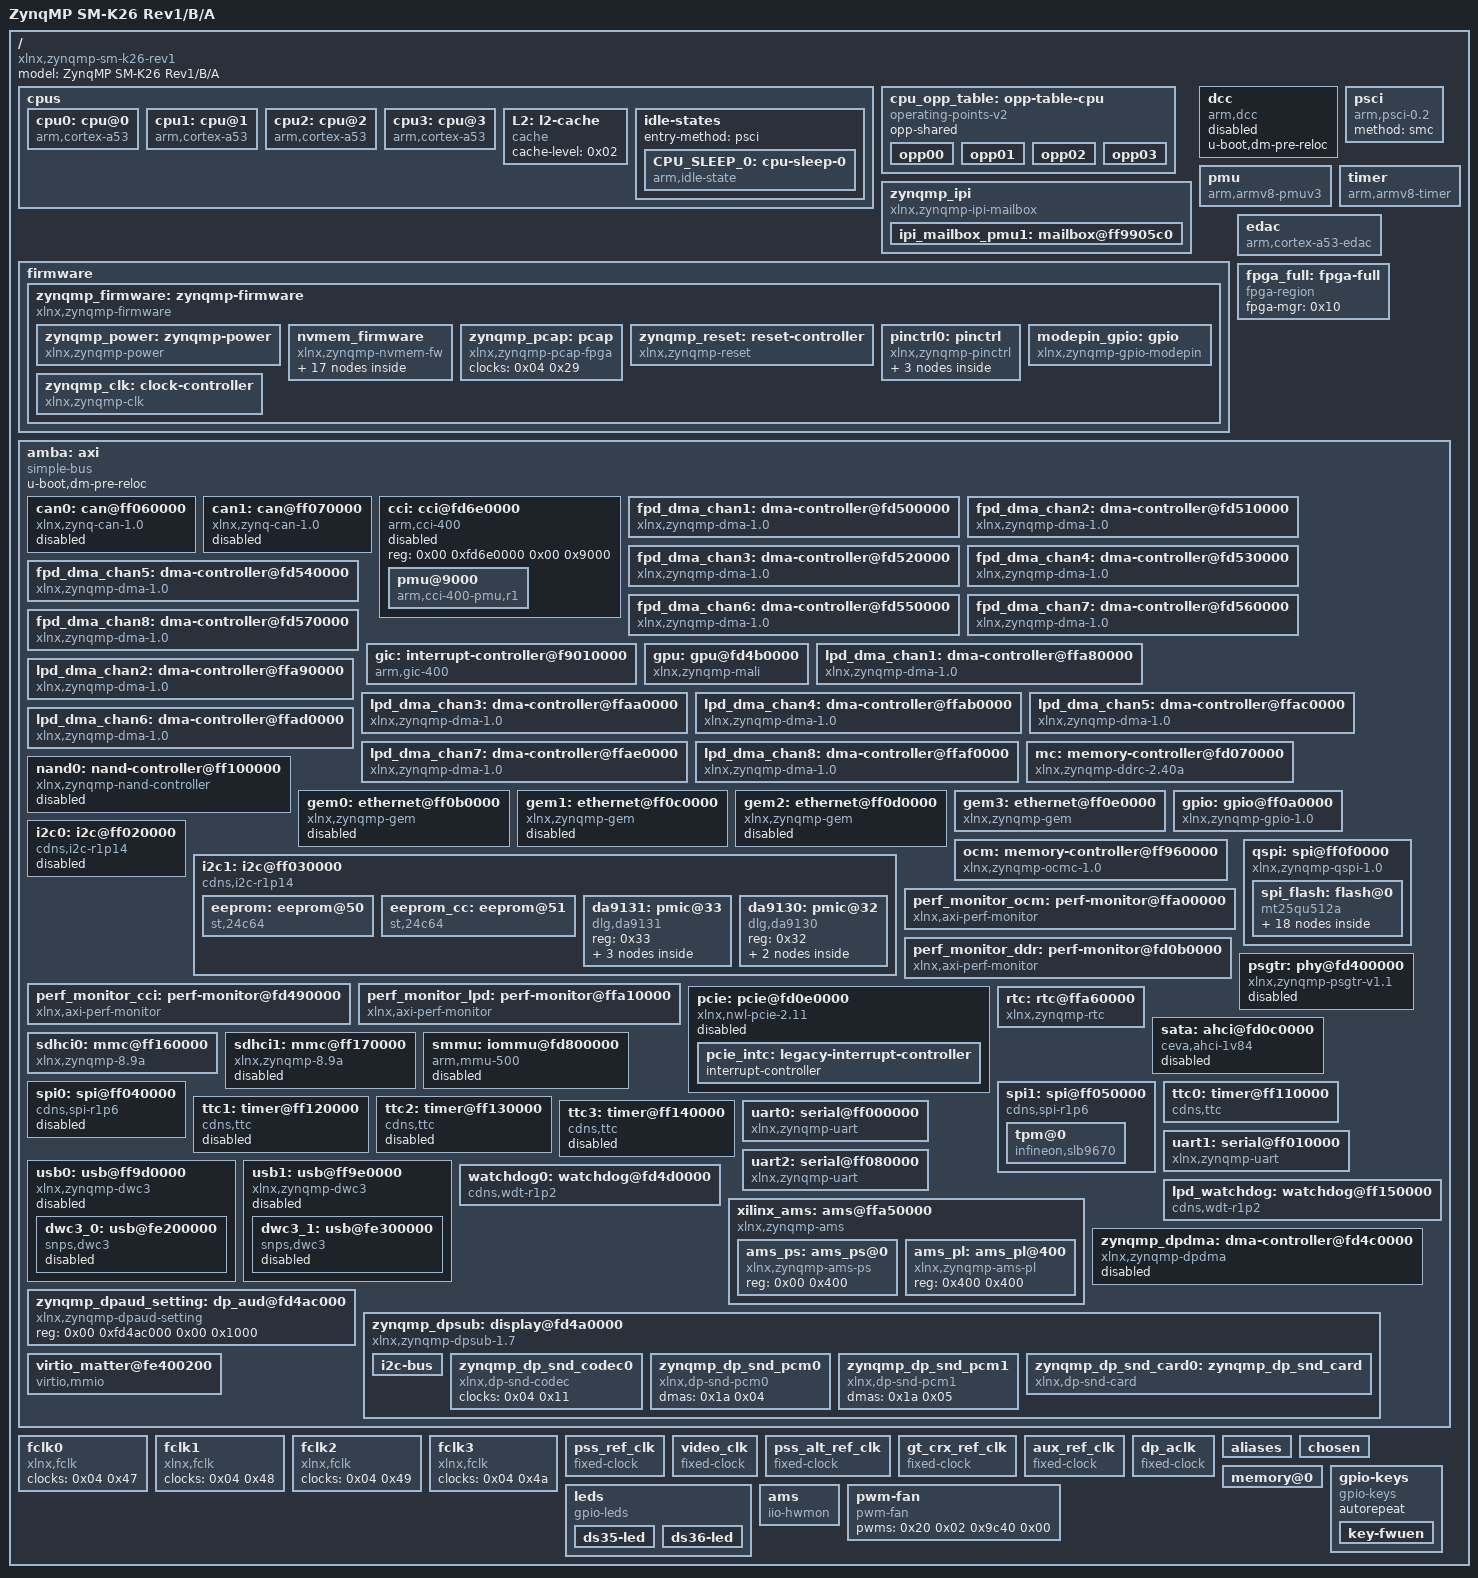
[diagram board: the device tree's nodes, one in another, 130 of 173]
/dts-v1/;

/ {
	compatible = "xlnx,zynqmp-sm-k26-rev1", "xlnx,zynqmp-sm-k26-revB", "xlnx,zynqmp-sm-k26-revA", "xlnx,zynqmp-sm-k26", "xlnx,zynqmp";
	#address-cells = <0x02>;
	#size-cells = <0x02>;
	model = "ZynqMP SM-K26 Rev1/B/A";

	cpus {
		#address-cells = <0x01>;
		#size-cells = <0x00>;

		cpu0: cpu@0 {
			compatible = "arm,cortex-a53";
			device_type = "cpu";
			enable-method = "psci";
			operating-points-v2 = <0x01>;
			reg = <0x00>;
			cpu-idle-states = <0x02>;
			next-level-cache = <0x03>;
			clocks = <0x04 0x0a>;
			phandle = <0x06>;
		};

		cpu1: cpu@1 {
			compatible = "arm,cortex-a53";
			device_type = "cpu";
			enable-method = "psci";
			reg = <0x01>;
			operating-points-v2 = <0x01>;
			cpu-idle-states = <0x02>;
			next-level-cache = <0x03>;
			phandle = <0x07>;
		};

		cpu2: cpu@2 {
			compatible = "arm,cortex-a53";
			device_type = "cpu";
			enable-method = "psci";
			reg = <0x02>;
			operating-points-v2 = <0x01>;
			cpu-idle-states = <0x02>;
			next-level-cache = <0x03>;
			phandle = <0x08>;
		};

		cpu3: cpu@3 {
			compatible = "arm,cortex-a53";
			device_type = "cpu";
			enable-method = "psci";
			reg = <0x03>;
			operating-points-v2 = <0x01>;
			cpu-idle-states = <0x02>;
			next-level-cache = <0x03>;
			phandle = <0x09>;
		};

		L2: l2-cache {
			compatible = "cache";
			cache-level = <0x02>;
			phandle = <0x03>;
		};

		idle-states {
			entry-method = "psci";

			CPU_SLEEP_0: cpu-sleep-0 {
				compatible = "arm,idle-state";
				arm,psci-suspend-param = <0x40000000>;
				local-timer-stop;
				entry-latency-us = <0x12c>;
				exit-latency-us = <0x258>;
				min-residency-us = <0x2710>;
				phandle = <0x02>;
			};
		};
	};

	cpu_opp_table: opp-table-cpu {
		compatible = "operating-points-v2";
		opp-shared;
		phandle = <0x01>;

		opp00 {
			opp-hz = <0x00 0x4f790d55>;
			opp-microvolt = <0xf4240>;
			clock-latency-ns = <0x7a120>;
		};

		opp01 {
			opp-hz = <0x00 0x27bc86aa>;
			opp-microvolt = <0xf4240>;
			clock-latency-ns = <0x7a120>;
		};

		opp02 {
			opp-hz = <0x00 0x1a7daf1c>;
			opp-microvolt = <0xf4240>;
			clock-latency-ns = <0x7a120>;
		};

		opp03 {
			opp-hz = <0x00 0x13de4355>;
			opp-microvolt = <0xf4240>;
			clock-latency-ns = <0x7a120>;
		};
	};

	zynqmp_ipi: zynqmp_ipi {
		u-boot,dm-pre-reloc;
		compatible = "xlnx,zynqmp-ipi-mailbox";
		interrupt-parent = <0x05>;
		interrupts = <0x00 0x23 0x04>;
		xlnx,ipi-id = <0x00>;
		#address-cells = <0x02>;
		#size-cells = <0x02>;
		ranges;
		phandle = <0x21>;

		ipi_mailbox_pmu1: mailbox@ff9905c0 {
			u-boot,dm-pre-reloc;
			reg = <0x00 0xff9905c0 0x00 0x20 0x00 0xff9905e0 0x00 0x20 0x00 0xff990e80 0x00 0x20 0x00 0xff990ea0 0x00 0x20>;
			reg-names = "local_request_region", "local_response_region", "remote_request_region", "remote_response_region";
			#mbox-cells = <0x01>;
			xlnx,ipi-id = <0x04>;
			phandle = <0x0a>;
		};
	};

	dcc: dcc {
		compatible = "arm,dcc";
		status = "disabled";
		u-boot,dm-pre-reloc;
		phandle = <0x22>;
	};

	pmu {
		compatible = "arm,armv8-pmuv3";
		interrupt-parent = <0x05>;
		interrupts = <0x00 0x8f 0x04 0x00 0x90 0x04 0x00 0x91 0x04 0x00 0x92 0x04>;
		interrupt-affinity = <0x06 0x07 0x08 0x09>;
	};

	psci {
		compatible = "arm,psci-0.2";
		method = "smc";
	};

	firmware {

		zynqmp_firmware: zynqmp-firmware {
			compatible = "xlnx,zynqmp-firmware";
			#power-domain-cells = <0x01>;
			method = "smc";
			u-boot,dm-pre-reloc;
			phandle = <0x11>;

			zynqmp_power: zynqmp-power {
				u-boot,dm-pre-reloc;
				compatible = "xlnx,zynqmp-power";
				interrupt-parent = <0x05>;
				interrupts = <0x00 0x23 0x04>;
				mboxes = <0x0a 0x00 0x0a 0x01>;
				mbox-names = "tx", "rx";
				phandle = <0x23>;
			};

			nvmem_firmware {
				compatible = "xlnx,zynqmp-nvmem-fw";
				#address-cells = <0x01>;
				#size-cells = <0x01>;

				soc_revision: soc_revision@0 {
					reg = <0x00 0x04>;
					phandle = <0x24>;
				};

				efuse_dna: efuse_dna@c {
					reg = <0x0c 0x0c>;
					phandle = <0x25>;
				};

				efuse_usr0: efuse_usr0@20 {
					reg = <0x20 0x04>;
					phandle = <0x26>;
				};

				efuse_usr1: efuse_usr1@24 {
					reg = <0x24 0x04>;
					phandle = <0x27>;
				};

				efuse_usr2: efuse_usr2@28 {
					reg = <0x28 0x04>;
					phandle = <0x28>;
				};

				efuse_usr3: efuse_usr3@2c {
					reg = <0x2c 0x04>;
					phandle = <0x29>;
				};

				efuse_usr4: efuse_usr4@30 {
					reg = <0x30 0x04>;
					phandle = <0x2a>;
				};

				efuse_usr5: efuse_usr5@34 {
					reg = <0x34 0x04>;
					phandle = <0x2b>;
				};

				efuse_usr6: efuse_usr6@38 {
					reg = <0x38 0x04>;
					phandle = <0x2c>;
				};

				efuse_usr7: efuse_usr7@3c {
					reg = <0x3c 0x04>;
					phandle = <0x2d>;
				};

				efuse_miscusr: efuse_miscusr@40 {
					reg = <0x40 0x04>;
					phandle = <0x2e>;
				};

				efuse_chash: efuse_chash@50 {
					reg = <0x50 0x04>;
					phandle = <0x2f>;
				};

				efuse_pufmisc: efuse_pufmisc@54 {
					reg = <0x54 0x04>;
					phandle = <0x30>;
				};

				efuse_sec: efuse_sec@58 {
					reg = <0x58 0x04>;
					phandle = <0x31>;
				};

				efuse_spkid: efuse_spkid@5c {
					reg = <0x5c 0x04>;
					phandle = <0x32>;
				};

				efuse_ppk0hash: efuse_ppk0hash@a0 {
					reg = <0xa0 0x30>;
					phandle = <0x33>;
				};

				efuse_ppk1hash: efuse_ppk1hash@d0 {
					reg = <0xd0 0x30>;
					phandle = <0x34>;
				};
			};

			zynqmp_pcap: pcap {
				compatible = "xlnx,zynqmp-pcap-fpga";
				clock-names = "ref_clk";
				clocks = <0x04 0x29>;
				phandle = <0x10>;
			};

			zynqmp_reset: reset-controller {
				compatible = "xlnx,zynqmp-reset";
				#reset-cells = <0x01>;
				phandle = <0x13>;
			};

			pinctrl0: pinctrl {
				compatible = "xlnx,zynqmp-pinctrl";
				status = "okay";
				phandle = <0x35>;

				pinctrl_sdhci0_default: sdhci0-default {
					phandle = <0x17>;

					conf {
						groups = "sdio0_0_grp";
						slew-rate = <0x01>;
						power-source = <0x01>;
						bias-disable;
					};

					mux {
						groups = "sdio0_0_grp";
						function = "sdio0";
					};
				};
			};

			modepin_gpio: gpio {
				compatible = "xlnx,zynqmp-gpio-modepin";
				gpio-controller;
				#gpio-cells = <0x02>;
				label = "modepin";
				phandle = <0x18>;
			};

			zynqmp_clk: clock-controller {
				u-boot,dm-pre-reloc;
				#clock-cells = <0x01>;
				compatible = "xlnx,zynqmp-clk";
				clocks = <0x0b 0x0c 0x0d 0x0e 0x0f>;
				clock-names = "pss_ref_clk", "video_clk", "pss_alt_ref_clk", "aux_ref_clk", "gt_crx_ref_clk";
				phandle = <0x04>;
			};
		};
	};

	timer {
		compatible = "arm,armv8-timer";
		interrupt-parent = <0x05>;
		interrupts = <0x01 0x0d 0xf08 0x01 0x0e 0xf08 0x01 0x0b 0xf08 0x01 0x0a 0xf08>;
	};

	edac {
		compatible = "arm,cortex-a53-edac";
	};

	fpga_full: fpga-full {
		compatible = "fpga-region";
		fpga-mgr = <0x10>;
		#address-cells = <0x02>;
		#size-cells = <0x02>;
		ranges;
		phandle = <0x36>;
	};

	amba: axi {
		compatible = "simple-bus";
		u-boot,dm-pre-reloc;
		#address-cells = <0x02>;
		#size-cells = <0x02>;
		ranges;
		phandle = <0x37>;

		can0: can@ff060000 {
			compatible = "xlnx,zynq-can-1.0";
			status = "disabled";
			clock-names = "can_clk", "pclk";
			reg = <0x00 0xff060000 0x00 0x1000>;
			interrupts = <0x00 0x17 0x04>;
			interrupt-parent = <0x05>;
			tx-fifo-depth = <0x40>;
			rx-fifo-depth = <0x40>;
			power-domains = <0x11 0x2f>;
			clocks = <0x04 0x3f 0x04 0x1f>;
			phandle = <0x38>;
		};

		can1: can@ff070000 {
			compatible = "xlnx,zynq-can-1.0";
			status = "disabled";
			clock-names = "can_clk", "pclk";
			reg = <0x00 0xff070000 0x00 0x1000>;
			interrupts = <0x00 0x18 0x04>;
			interrupt-parent = <0x05>;
			tx-fifo-depth = <0x40>;
			rx-fifo-depth = <0x40>;
			power-domains = <0x11 0x30>;
			clocks = <0x04 0x40 0x04 0x1f>;
			phandle = <0x39>;
		};

		cci: cci@fd6e0000 {
			compatible = "arm,cci-400";
			status = "disabled";
			reg = <0x00 0xfd6e0000 0x00 0x9000>;
			ranges = <0x00 0x00 0xfd6e0000 0x10000>;
			#address-cells = <0x01>;
			#size-cells = <0x01>;
			phandle = <0x3a>;

			pmu@9000 {
				compatible = "arm,cci-400-pmu,r1";
				reg = <0x9000 0x5000>;
				interrupt-parent = <0x05>;
				interrupts = <0x00 0x7b 0x04 0x00 0x7b 0x04 0x00 0x7b 0x04 0x00 0x7b 0x04 0x00 0x7b 0x04>;
			};
		};

		fpd_dma_chan1: dma-controller@fd500000 {
			status = "okay";
			compatible = "xlnx,zynqmp-dma-1.0";
			reg = <0x00 0xfd500000 0x00 0x1000>;
			interrupt-parent = <0x05>;
			interrupts = <0x00 0x7c 0x04>;
			clock-names = "clk_main", "clk_apb";
			#dma-cells = <0x01>;
			xlnx,bus-width = <0x80>;
			iommus = <0x12 0x14e8>;
			power-domains = <0x11 0x2a>;
			clocks = <0x04 0x13 0x04 0x1f>;
			phandle = <0x3b>;
		};

		fpd_dma_chan2: dma-controller@fd510000 {
			status = "okay";
			compatible = "xlnx,zynqmp-dma-1.0";
			reg = <0x00 0xfd510000 0x00 0x1000>;
			interrupt-parent = <0x05>;
			interrupts = <0x00 0x7d 0x04>;
			clock-names = "clk_main", "clk_apb";
			#dma-cells = <0x01>;
			xlnx,bus-width = <0x80>;
			iommus = <0x12 0x14e9>;
			power-domains = <0x11 0x2a>;
			clocks = <0x04 0x13 0x04 0x1f>;
			phandle = <0x3c>;
		};

		fpd_dma_chan3: dma-controller@fd520000 {
			status = "okay";
			compatible = "xlnx,zynqmp-dma-1.0";
			reg = <0x00 0xfd520000 0x00 0x1000>;
			interrupt-parent = <0x05>;
			interrupts = <0x00 0x7e 0x04>;
			clock-names = "clk_main", "clk_apb";
			#dma-cells = <0x01>;
			xlnx,bus-width = <0x80>;
			iommus = <0x12 0x14ea>;
			power-domains = <0x11 0x2a>;
			clocks = <0x04 0x13 0x04 0x1f>;
			phandle = <0x3d>;
		};

		fpd_dma_chan4: dma-controller@fd530000 {
			status = "okay";
			compatible = "xlnx,zynqmp-dma-1.0";
			reg = <0x00 0xfd530000 0x00 0x1000>;
			interrupt-parent = <0x05>;
			interrupts = <0x00 0x7f 0x04>;
			clock-names = "clk_main", "clk_apb";
			#dma-cells = <0x01>;
			xlnx,bus-width = <0x80>;
			iommus = <0x12 0x14eb>;
			power-domains = <0x11 0x2a>;
			clocks = <0x04 0x13 0x04 0x1f>;
			phandle = <0x3e>;
		};

		fpd_dma_chan5: dma-controller@fd540000 {
			status = "okay";
			compatible = "xlnx,zynqmp-dma-1.0";
			reg = <0x00 0xfd540000 0x00 0x1000>;
			interrupt-parent = <0x05>;
			interrupts = <0x00 0x80 0x04>;
			clock-names = "clk_main", "clk_apb";
			#dma-cells = <0x01>;
			xlnx,bus-width = <0x80>;
			iommus = <0x12 0x14ec>;
			power-domains = <0x11 0x2a>;
			clocks = <0x04 0x13 0x04 0x1f>;
			phandle = <0x3f>;
		};

		fpd_dma_chan6: dma-controller@fd550000 {
			status = "okay";
			compatible = "xlnx,zynqmp-dma-1.0";
			reg = <0x00 0xfd550000 0x00 0x1000>;
			interrupt-parent = <0x05>;
			interrupts = <0x00 0x81 0x04>;
			clock-names = "clk_main", "clk_apb";
			#dma-cells = <0x01>;
			xlnx,bus-width = <0x80>;
			iommus = <0x12 0x14ed>;
			power-domains = <0x11 0x2a>;
			clocks = <0x04 0x13 0x04 0x1f>;
			phandle = <0x40>;
		};

		fpd_dma_chan7: dma-controller@fd560000 {
			status = "okay";
			compatible = "xlnx,zynqmp-dma-1.0";
			reg = <0x00 0xfd560000 0x00 0x1000>;
			interrupt-parent = <0x05>;
			interrupts = <0x00 0x82 0x04>;
			clock-names = "clk_main", "clk_apb";
			#dma-cells = <0x01>;
			xlnx,bus-width = <0x80>;
			iommus = <0x12 0x14ee>;
			power-domains = <0x11 0x2a>;
			clocks = <0x04 0x13 0x04 0x1f>;
			phandle = <0x41>;
		};

		fpd_dma_chan8: dma-controller@fd570000 {
			status = "okay";
			compatible = "xlnx,zynqmp-dma-1.0";
			reg = <0x00 0xfd570000 0x00 0x1000>;
			interrupt-parent = <0x05>;
			interrupts = <0x00 0x83 0x04>;
			clock-names = "clk_main", "clk_apb";
			#dma-cells = <0x01>;
			xlnx,bus-width = <0x80>;
			iommus = <0x12 0x14ef>;
			power-domains = <0x11 0x2a>;
			clocks = <0x04 0x13 0x04 0x1f>;
			phandle = <0x42>;
		};

		gic: interrupt-controller@f9010000 {
			compatible = "arm,gic-400";
			#interrupt-cells = <0x03>;
			reg = <0x00 0xf9010000 0x00 0x10000 0x00 0xf9020000 0x00 0x20000 0x00 0xf9040000 0x00 0x20000 0x00 0xf9060000 0x00 0x20000>;
			interrupt-controller;
			interrupt-parent = <0x05>;
			interrupts = <0x01 0x09 0xf04>;
			phandle = <0x05>;
		};

		gpu: gpu@fd4b0000 {
			status = "okay";
			compatible = "xlnx,zynqmp-mali", "arm,mali-400";
			reg = <0x00 0xfd4b0000 0x00 0x10000>;
			interrupt-parent = <0x05>;
			interrupts = <0x00 0x84 0x04 0x00 0x84 0x04 0x00 0x84 0x04 0x00 0x84 0x04 0x00 0x84 0x04 0x00 0x84 0x04>;
			interrupt-names = "gp", "gpmmu", "pp0", "ppmmu0", "pp1", "ppmmu1";
			clock-names = "bus", "core";
			power-domains = <0x11 0x3a>;
			clocks = <0x04 0x18 0x04 0x19>;
			phandle = <0x43>;
		};

		lpd_dma_chan1: dma-controller@ffa80000 {
			status = "okay";
			compatible = "xlnx,zynqmp-dma-1.0";
			reg = <0x00 0xffa80000 0x00 0x1000>;
			interrupt-parent = <0x05>;
			interrupts = <0x00 0x4d 0x04>;
			clock-names = "clk_main", "clk_apb";
			#dma-cells = <0x01>;
			xlnx,bus-width = <0x40>;
			power-domains = <0x11 0x2b>;
			clocks = <0x04 0x44 0x04 0x1f>;
			phandle = <0x44>;
		};

		lpd_dma_chan2: dma-controller@ffa90000 {
			status = "okay";
			compatible = "xlnx,zynqmp-dma-1.0";
			reg = <0x00 0xffa90000 0x00 0x1000>;
			interrupt-parent = <0x05>;
			interrupts = <0x00 0x4e 0x04>;
			clock-names = "clk_main", "clk_apb";
			#dma-cells = <0x01>;
			xlnx,bus-width = <0x40>;
			power-domains = <0x11 0x2b>;
			clocks = <0x04 0x44 0x04 0x1f>;
			phandle = <0x45>;
		};

		lpd_dma_chan3: dma-controller@ffaa0000 {
			status = "okay";
			compatible = "xlnx,zynqmp-dma-1.0";
			reg = <0x00 0xffaa0000 0x00 0x1000>;
			interrupt-parent = <0x05>;
			interrupts = <0x00 0x4f 0x04>;
			clock-names = "clk_main", "clk_apb";
			#dma-cells = <0x01>;
			xlnx,bus-width = <0x40>;
			power-domains = <0x11 0x2b>;
			clocks = <0x04 0x44 0x04 0x1f>;
			phandle = <0x46>;
		};

		lpd_dma_chan4: dma-controller@ffab0000 {
			status = "okay";
			compatible = "xlnx,zynqmp-dma-1.0";
			reg = <0x00 0xffab0000 0x00 0x1000>;
			interrupt-parent = <0x05>;
			interrupts = <0x00 0x50 0x04>;
			clock-names = "clk_main", "clk_apb";
			#dma-cells = <0x01>;
			xlnx,bus-width = <0x40>;
			power-domains = <0x11 0x2b>;
			clocks = <0x04 0x44 0x04 0x1f>;
			phandle = <0x47>;
		};

		lpd_dma_chan5: dma-controller@ffac0000 {
			status = "okay";
			compatible = "xlnx,zynqmp-dma-1.0";
			reg = <0x00 0xffac0000 0x00 0x1000>;
			interrupt-parent = <0x05>;
			interrupts = <0x00 0x51 0x04>;
			clock-names = "clk_main", "clk_apb";
			#dma-cells = <0x01>;
			xlnx,bus-width = <0x40>;
			power-domains = <0x11 0x2b>;
			clocks = <0x04 0x44 0x04 0x1f>;
			phandle = <0x48>;
		};

		lpd_dma_chan6: dma-controller@ffad0000 {
			status = "okay";
			compatible = "xlnx,zynqmp-dma-1.0";
			reg = <0x00 0xffad0000 0x00 0x1000>;
			interrupt-parent = <0x05>;
			interrupts = <0x00 0x52 0x04>;
			clock-names = "clk_main", "clk_apb";
			#dma-cells = <0x01>;
			xlnx,bus-width = <0x40>;
			power-domains = <0x11 0x2b>;
			clocks = <0x04 0x44 0x04 0x1f>;
			phandle = <0x49>;
		};

		lpd_dma_chan7: dma-controller@ffae0000 {
			status = "okay";
			compatible = "xlnx,zynqmp-dma-1.0";
			reg = <0x00 0xffae0000 0x00 0x1000>;
			interrupt-parent = <0x05>;
			interrupts = <0x00 0x53 0x04>;
			clock-names = "clk_main", "clk_apb";
			#dma-cells = <0x01>;
			xlnx,bus-width = <0x40>;
			power-domains = <0x11 0x2b>;
			clocks = <0x04 0x44 0x04 0x1f>;
			phandle = <0x4a>;
		};

		lpd_dma_chan8: dma-controller@ffaf0000 {
			status = "okay";
			compatible = "xlnx,zynqmp-dma-1.0";
			reg = <0x00 0xffaf0000 0x00 0x1000>;
			interrupt-parent = <0x05>;
			interrupts = <0x00 0x54 0x04>;
			clock-names = "clk_main", "clk_apb";
			#dma-cells = <0x01>;
			xlnx,bus-width = <0x40>;
			power-domains = <0x11 0x2b>;
			clocks = <0x04 0x44 0x04 0x1f>;
			phandle = <0x4b>;
		};

		mc: memory-controller@fd070000 {
			compatible = "xlnx,zynqmp-ddrc-2.40a";
			reg = <0x00 0xfd070000 0x00 0x30000>;
			interrupt-parent = <0x05>;
			interrupts = <0x00 0x70 0x04>;
			phandle = <0x4c>;
		};

		nand0: nand-controller@ff100000 {
			compatible = "xlnx,zynqmp-nand-controller", "arasan,nfc-v3p10";
			status = "disabled";
			reg = <0x00 0xff100000 0x00 0x1000>;
			clock-names = "controller", "bus";
			interrupt-parent = <0x05>;
			interrupts = <0x00 0x0e 0x04>;
			#address-cells = <0x01>;
			#size-cells = <0x00>;
			iommus = <0x12 0x872>;
			power-domains = <0x11 0x2c>;
			clocks = <0x04 0x3c 0x04 0x1f>;
			phandle = <0x4d>;
		};

		gem0: ethernet@ff0b0000 {
			compatible = "xlnx,zynqmp-gem", "cdns,gem";
			status = "disabled";
			interrupt-parent = <0x05>;
			interrupts = <0x00 0x39 0x04 0x00 0x39 0x04>;
			reg = <0x00 0xff0b0000 0x00 0x1000>;
			clock-names = "pclk", "hclk", "tx_clk", "rx_clk", "tsu_clk";
			#address-cells = <0x01>;
			#size-cells = <0x00>;
			iommus = <0x12 0x874>;
			power-domains = <0x11 0x1d>;
			resets = <0x13 0x1d>;
			reset-names = "gem0_rst";
			clocks = <0x04 0x1f 0x04 0x68 0x04 0x2d 0x04 0x31 0x04 0x2c>;
			phandle = <0x4e>;
		};

		gem1: ethernet@ff0c0000 {
			compatible = "xlnx,zynqmp-gem", "cdns,gem";
			status = "disabled";
			interrupt-parent = <0x05>;
			interrupts = <0x00 0x3b 0x04 0x00 0x3b 0x04>;
			reg = <0x00 0xff0c0000 0x00 0x1000>;
			clock-names = "pclk", "hclk", "tx_clk", "rx_clk", "tsu_clk";
			#address-cells = <0x01>;
			#size-cells = <0x00>;
			iommus = <0x12 0x875>;
			power-domains = <0x11 0x1e>;
			resets = <0x13 0x1e>;
			reset-names = "gem1_rst";
			clocks = <0x04 0x1f 0x04 0x69 0x04 0x2e 0x04 0x32 0x04 0x2c>;
			phandle = <0x4f>;
		};

		gem2: ethernet@ff0d0000 {
			compatible = "xlnx,zynqmp-gem", "cdns,gem";
			status = "disabled";
			interrupt-parent = <0x05>;
			interrupts = <0x00 0x3d 0x04 0x00 0x3d 0x04>;
			reg = <0x00 0xff0d0000 0x00 0x1000>;
			clock-names = "pclk", "hclk", "tx_clk", "rx_clk", "tsu_clk";
			#address-cells = <0x01>;
			#size-cells = <0x00>;
			iommus = <0x12 0x876>;
			power-domains = <0x11 0x1f>;
			resets = <0x13 0x1f>;
			reset-names = "gem2_rst";
			clocks = <0x04 0x1f 0x04 0x6a 0x04 0x2f 0x04 0x33 0x04 0x2c>;
			phandle = <0x50>;
		};

		gem3: ethernet@ff0e0000 {
			compatible = "xlnx,zynqmp-gem", "cdns,gem";
			status = "okay";
			interrupt-parent = <0x05>;
			interrupts = <0x00 0x3f 0x04 0x00 0x3f 0x04>;
			reg = <0x00 0xff0e0000 0x00 0x1000>;
			clock-names = "pclk", "hclk", "tx_clk", "rx_clk", "tsu_clk";
			#address-cells = <0x01>;
			#size-cells = <0x00>;
			iommus = <0x12 0x877>;
			power-domains = <0x11 0x20>;
			resets = <0x13 0x20>;
			reset-names = "gem3_rst";
			clocks = <0x04 0x1f 0x04 0x6b 0x04 0x30 0x04 0x34 0x04 0x2c>;
			phandle = <0x51>;
		};

		gpio: gpio@ff0a0000 {
			compatible = "xlnx,zynqmp-gpio-1.0";
			status = "okay";
			#gpio-cells = <0x02>;
			gpio-controller;
			interrupt-parent = <0x05>;
			interrupts = <0x00 0x10 0x04>;
			interrupt-controller;
			#interrupt-cells = <0x02>;
			reg = <0x00 0xff0a0000 0x00 0x1000>;
			power-domains = <0x11 0x2e>;
			clocks = <0x04 0x1f>;
			gpio-line-names = "QSPI_CLK", "QSPI_DQ1", "QSPI_DQ2", "QSPI_DQ3", "QSPI_DQ0", "QSPI_CS_B", "SPI_CLK", "LED1", "LED2", "SPI_CS_B", "SPI_MISO", "SPI_MOSI", "FWUEN", "EMMC_DAT0", "EMMC_DAT1", "EMMC_DAT2", "EMMC_DAT3", "EMMC_DAT4", "EMMC_DAT5", "EMMC_DAT6", "EMMC_DAT7", "EMMC_CMD", "EMMC_CLK", "EMMC_RST", "I2C1_SCL", "I2C1_SDA", "", "", "", "", "", "", "", "", "", "", "", "", "", "", "", "", "", "", "", "", "", "", "", "", "", "", "", "", "", "", "", "", "", "", "", "", "", "", "", "", "", "", "", "", "", "", "", "", "", "", "", "", "", "", "", "", "", "", "", "", "", "", "", "", "", "", "", "", "", "", "", "", "", "", "", "", "", "", "", "", "", "", "", "", "", "", "", "", "", "", "", "", "", "", "", "", "", "", "", "", "", "", "", "", "", "", "", "", "", "", "", "", "", "", "", "", "", "", "", "", "", "", "", "", "", "", "", "", "", "", "", "", "", "", "", "", "", "", "", "", "", "", "", "", "", "", "", "";
			phandle = <0x14>;
		};

		i2c0: i2c@ff020000 {
			compatible = "cdns,i2c-r1p14";
			status = "disabled";
			interrupt-parent = <0x05>;
			interrupts = <0x00 0x11 0x04>;
			reg = <0x00 0xff020000 0x00 0x1000>;
			#address-cells = <0x01>;
			#size-cells = <0x00>;
			power-domains = <0x11 0x25>;
			clocks = <0x04 0x3d>;
			phandle = <0x52>;
		};

		i2c1: i2c@ff030000 {
			compatible = "cdns,i2c-r1p14";
			status = "okay";
			interrupt-parent = <0x05>;
			interrupts = <0x00 0x12 0x04>;
			reg = <0x00 0xff030000 0x00 0x1000>;
			#address-cells = <0x01>;
			#size-cells = <0x00>;
			power-domains = <0x11 0x26>;
			clocks = <0x04 0x3e>;
			u-boot,dm-pre-reloc;
			clock-frequency = <0x61a80>;
			scl-gpios = <0x14 0x18 0x00>;
			sda-gpios = <0x14 0x19 0x00>;
			phandle = <0x53>;

			eeprom: eeprom@50 {
				u-boot,dm-pre-reloc;
				compatible = "st,24c64", "atmel,24c64";
				reg = <0x50>;
				phandle = <0x54>;
			};

			eeprom_cc: eeprom@51 {
				u-boot,dm-pre-reloc;
				compatible = "st,24c64", "atmel,24c64";
				reg = <0x51>;
				phandle = <0x55>;
			};

			da9131: pmic@33 {
				compatible = "dlg,da9131";
				reg = <0x33>;
				phandle = <0x56>;

				regulators {

					da9131_buck1: buck1 {
						regulator-name = "da9131_buck1";
						regulator-boot-on;
						regulator-always-on;
						phandle = <0x57>;
					};

					da9131_buck2: buck2 {
						regulator-name = "da9131_buck2";
						regulator-boot-on;
						regulator-always-on;
						phandle = <0x58>;
					};
				};
			};

			da9130: pmic@32 {
				compatible = "dlg,da9130";
				reg = <0x32>;
				phandle = <0x59>;

				regulators {

					da9130_buck1: buck1 {
						regulator-name = "da9130_buck1";
						regulator-boot-on;
						regulator-always-on;
						phandle = <0x5a>;
					};
				};
			};
		};

		ocm: memory-controller@ff960000 {
			compatible = "xlnx,zynqmp-ocmc-1.0";
			reg = <0x00 0xff960000 0x00 0x1000>;
			interrupt-parent = <0x05>;
			interrupts = <0x00 0x0a 0x04>;
			phandle = <0x5b>;
		};

		perf_monitor_ocm: perf-monitor@ffa00000 {
			compatible = "xlnx,axi-perf-monitor";
			reg = <0x00 0xffa00000 0x00 0x10000>;
			interrupts = <0x00 0x19 0x04>;
			interrupt-parent = <0x05>;
			xlnx,enable-profile = <0x00>;
			xlnx,enable-trace = <0x00>;
			xlnx,num-monitor-slots = <0x01>;
			xlnx,enable-event-count = <0x01>;
			xlnx,enable-event-log = <0x01>;
			xlnx,have-sampled-metric-cnt = <0x01>;
			xlnx,num-of-counters = <0x08>;
			xlnx,metric-count-width = <0x20>;
			xlnx,metrics-sample-count-width = <0x20>;
			xlnx,global-count-width = <0x20>;
			xlnx,metric-count-scale = <0x01>;
			clocks = <0x04 0x1f>;
			phandle = <0x5c>;
		};

		perf_monitor_ddr: perf-monitor@fd0b0000 {
			compatible = "xlnx,axi-perf-monitor";
			reg = <0x00 0xfd0b0000 0x00 0x10000>;
			interrupts = <0x00 0x7b 0x04>;
			interrupt-parent = <0x05>;
			xlnx,enable-profile = <0x00>;
			xlnx,enable-trace = <0x00>;
			xlnx,num-monitor-slots = <0x06>;
			xlnx,enable-event-count = <0x01>;
			xlnx,enable-event-log = <0x00>;
			xlnx,have-sampled-metric-cnt = <0x01>;
			xlnx,num-of-counters = <0x0a>;
			xlnx,metric-count-width = <0x20>;
			xlnx,metrics-sample-count-width = <0x20>;
			xlnx,global-count-width = <0x20>;
			xlnx,metric-count-scale = <0x01>;
			clocks = <0x04 0x1c>;
			phandle = <0x5d>;
		};

		perf_monitor_cci: perf-monitor@fd490000 {
			compatible = "xlnx,axi-perf-monitor";
			reg = <0x00 0xfd490000 0x00 0x10000>;
			interrupts = <0x00 0x7b 0x04>;
			interrupt-parent = <0x05>;
			xlnx,enable-profile = <0x00>;
			xlnx,enable-trace = <0x00>;
			xlnx,num-monitor-slots = <0x01>;
			xlnx,enable-event-count = <0x01>;
			xlnx,enable-event-log = <0x00>;
			xlnx,have-sampled-metric-cnt = <0x01>;
			xlnx,num-of-counters = <0x08>;
			xlnx,metric-count-width = <0x20>;
			xlnx,metrics-sample-count-width = <0x20>;
			xlnx,global-count-width = <0x20>;
			xlnx,metric-count-scale = <0x01>;
			clocks = <0x04 0x1c>;
			phandle = <0x5e>;
		};

		perf_monitor_lpd: perf-monitor@ffa10000 {
			compatible = "xlnx,axi-perf-monitor";
			reg = <0x00 0xffa10000 0x00 0x10000>;
			interrupts = <0x00 0x19 0x04>;
			interrupt-parent = <0x05>;
			xlnx,enable-profile = <0x00>;
			xlnx,enable-trace = <0x00>;
			xlnx,num-monitor-slots = <0x01>;
			xlnx,enable-event-count = <0x01>;
			xlnx,enable-event-log = <0x01>;
			xlnx,have-sampled-metric-cnt = <0x01>;
			xlnx,num-of-counters = <0x08>;
			xlnx,metric-count-width = <0x20>;
			xlnx,metrics-sample-count-width = <0x20>;
			xlnx,global-count-width = <0x20>;
			xlnx,metric-count-scale = <0x01>;
			clocks = <0x04 0x1f>;
			phandle = <0x5f>;
		};

		pcie: pcie@fd0e0000 {
			compatible = "xlnx,nwl-pcie-2.11";
			status = "disabled";
			#address-cells = <0x03>;
			#size-cells = <0x02>;
			#interrupt-cells = <0x01>;
			msi-controller;
			device_type = "pci";
			interrupt-parent = <0x05>;
			interrupts = <0x00 0x76 0x04 0x00 0x75 0x04 0x00 0x74 0x04 0x00 0x73 0x04 0x00 0x72 0x04>;
			interrupt-names = "misc", "dummy", "intx", "msi1", "msi0";
			msi-parent = <0x15>;
			reg = <0x00 0xfd0e0000 0x00 0x1000 0x00 0xfd480000 0x00 0x1000 0x80 0x00 0x00 0x1000000>;
			reg-names = "breg", "pcireg", "cfg";
			ranges = <0x2000000 0x00 0xe0000000 0x00 0xe0000000 0x00 0x10000000 0x43000000 0x06 0x00 0x06 0x00 0x02 0x00>;
			bus-range = <0x00 0xff>;
			interrupt-map-mask = <0x00 0x00 0x00 0x07>;
			interrupt-map = <0x00 0x00 0x00 0x01 0x16 0x01 0x00 0x00 0x00 0x02 0x16 0x02 0x00 0x00 0x00 0x03 0x16 0x03 0x00 0x00 0x00 0x04 0x16 0x04>;
			iommus = <0x12 0x4d0>;
			power-domains = <0x11 0x3b>;
			clocks = <0x04 0x17>;
			phandle = <0x15>;

			pcie_intc: legacy-interrupt-controller {
				interrupt-controller;
				#address-cells = <0x00>;
				#interrupt-cells = <0x01>;
				phandle = <0x16>;
			};
		};

		qspi: spi@ff0f0000 {
			u-boot,dm-pre-reloc;
			compatible = "xlnx,zynqmp-qspi-1.0";
			status = "okay";
			clock-names = "ref_clk", "pclk";
			interrupts = <0x00 0x0f 0x04>;
			interrupt-parent = <0x05>;
			num-cs = <0x01>;
			reg = <0x00 0xff0f0000 0x00 0x1000 0x00 0xc0000000 0x00 0x8000000>;
			#address-cells = <0x01>;
			#size-cells = <0x00>;
			iommus = <0x12 0x873>;
			power-domains = <0x11 0x2d>;
			clocks = <0x04 0x35 0x04 0x1f>;
			phandle = <0x60>;

			spi_flash: flash@0 {
				compatible = "mt25qu512a", "jedec,spi-nor";
				#address-cells = <0x01>;
				#size-cells = <0x01>;
				reg = <0x00>;
				spi-tx-bus-width = <0x04>;
				spi-rx-bus-width = <0x04>;
				spi-max-frequency = <0x2625a00>;
				phandle = <0x61>;

				partitions {
					compatible = "fixed-partitions";
					#address-cells = <0x01>;
					#size-cells = <0x01>;

					partition@0 {
						label = "Image Selector";
						reg = <0x00 0x80000>;
						read-only;
						lock;
					};

					partition@80000 {
						label = "Image Selector Golden";
						reg = <0x80000 0x80000>;
						read-only;
						lock;
					};

					partition@100000 {
						label = "Persistent Register";
						reg = <0x100000 0x20000>;
					};

					partition@120000 {
						label = "Persistent Register Backup";
						reg = <0x120000 0x20000>;
					};

					partition@140000 {
						label = "Open_1";
						reg = <0x140000 0xc0000>;
					};

					partition@200000 {
						label = "Image A (FSBL, PMU, ATF, U-Boot)";
						reg = <0x200000 0xd00000>;
					};

					partition@f00000 {
						label = "ImgSel Image A Catch";
						reg = <0xf00000 0x80000>;
						read-only;
						lock;
					};

					partition@f80000 {
						label = "Image B (FSBL, PMU, ATF, U-Boot)";
						reg = <0xf80000 0xd00000>;
					};

					partition@1c80000 {
						label = "ImgSel Image B Catch";
						reg = <0x1c80000 0x80000>;
						read-only;
						lock;
					};

					partition@1d00000 {
						label = "Open_2";
						reg = <0x1d00000 0x100000>;
					};

					partition@1e00000 {
						label = "Recovery Image";
						reg = <0x1e00000 0x200000>;
						read-only;
						lock;
					};

					partition@2000000 {
						label = "Recovery Image Backup";
						reg = <0x2000000 0x200000>;
						read-only;
						lock;
					};

					partition@2200000 {
						label = "U-Boot storage variables";
						reg = <0x2200000 0x20000>;
					};

					partition@2220000 {
						label = "U-Boot storage variables backup";
						reg = <0x2220000 0x20000>;
					};

					partition@2240000 {
						label = "SHA256";
						reg = <0x2240000 0x40000>;
						read-only;
						lock;
					};

					partition@2280000 {
						label = "Secure OS Storage";
						reg = <0x2280000 0x20000>;
					};

					partition@22A0000 {
						label = "User";
						reg = <0x22a0000 0x1db0000>;
					};
				};
			};
		};

		psgtr: phy@fd400000 {
			compatible = "xlnx,zynqmp-psgtr-v1.1";
			status = "disabled";
			reg = <0x00 0xfd400000 0x00 0x40000 0x00 0xfd3d0000 0x00 0x1000>;
			reg-names = "serdes", "siou";
			#phy-cells = <0x04>;
			phandle = <0x62>;
		};

		rtc: rtc@ffa60000 {
			compatible = "xlnx,zynqmp-rtc";
			status = "okay";
			reg = <0x00 0xffa60000 0x00 0x100>;
			interrupt-parent = <0x05>;
			interrupts = <0x00 0x1a 0x04 0x00 0x1b 0x04>;
			interrupt-names = "alarm", "sec";
			calibration = <0x7fff>;
			phandle = <0x63>;
		};

		sata: ahci@fd0c0000 {
			compatible = "ceva,ahci-1v84";
			status = "disabled";
			reg = <0x00 0xfd0c0000 0x00 0x2000>;
			interrupt-parent = <0x05>;
			interrupts = <0x00 0x85 0x04>;
			power-domains = <0x11 0x1c>;
			resets = <0x13 0x10>;
			clocks = <0x04 0x16>;
			phandle = <0x64>;
		};

		sdhci0: mmc@ff160000 {
			u-boot,dm-pre-reloc;
			compatible = "xlnx,zynqmp-8.9a", "arasan,sdhci-8.9a";
			status = "okay";
			interrupt-parent = <0x05>;
			interrupts = <0x00 0x30 0x04>;
			reg = <0x00 0xff160000 0x00 0x1000>;
			clock-names = "clk_xin", "clk_ahb";
			iommus = <0x12 0x870>;
			#clock-cells = <0x01>;
			clock-output-names = "clk_out_sd0", "clk_in_sd0";
			power-domains = <0x11 0x27>;
			resets = <0x13 0x26>;
			clocks = <0x04 0x36 0x04 0x1f>;
			assigned-clocks = <0x04 0x36>;
			pinctrl-names = "default";
			pinctrl-0 = <0x17>;
			non-removable;
			disable-wp;
			bus-width = <0x08>;
			xlnx,mio-bank = <0x00>;
			assigned-clock-rates = <0xb2cfe8b>;
			phandle = <0x65>;
		};

		sdhci1: mmc@ff170000 {
			u-boot,dm-pre-reloc;
			compatible = "xlnx,zynqmp-8.9a", "arasan,sdhci-8.9a";
			status = "disabled";
			interrupt-parent = <0x05>;
			interrupts = <0x00 0x31 0x04>;
			reg = <0x00 0xff170000 0x00 0x1000>;
			clock-names = "clk_xin", "clk_ahb";
			iommus = <0x12 0x871>;
			#clock-cells = <0x01>;
			clock-output-names = "clk_out_sd1", "clk_in_sd1";
			power-domains = <0x11 0x28>;
			resets = <0x13 0x27>;
			clocks = <0x04 0x37 0x04 0x1f>;
			assigned-clocks = <0x04 0x37>;
			phandle = <0x66>;
		};

		smmu: iommu@fd800000 {
			compatible = "arm,mmu-500";
			reg = <0x00 0xfd800000 0x00 0x20000>;
			#iommu-cells = <0x01>;
			status = "disabled";
			#global-interrupts = <0x01>;
			interrupt-parent = <0x05>;
			interrupts = <0x00 0x9b 0x04 0x00 0x9b 0x04 0x00 0x9b 0x04 0x00 0x9b 0x04 0x00 0x9b 0x04 0x00 0x9b 0x04 0x00 0x9b 0x04 0x00 0x9b 0x04 0x00 0x9b 0x04 0x00 0x9b 0x04 0x00 0x9b 0x04 0x00 0x9b 0x04 0x00 0x9b 0x04 0x00 0x9b 0x04 0x00 0x9b 0x04 0x00 0x9b 0x04 0x00 0x9b 0x04>;
			phandle = <0x12>;
		};

		spi0: spi@ff040000 {
			compatible = "cdns,spi-r1p6";
			status = "disabled";
			interrupt-parent = <0x05>;
			interrupts = <0x00 0x13 0x04>;
			reg = <0x00 0xff040000 0x00 0x1000>;
			clock-names = "ref_clk", "pclk";
			#address-cells = <0x01>;
			#size-cells = <0x00>;
			power-domains = <0x11 0x23>;
			clocks = <0x04 0x3a 0x04 0x1f>;
			phandle = <0x67>;
		};

		spi1: spi@ff050000 {
			compatible = "cdns,spi-r1p6";
			status = "okay";
			interrupt-parent = <0x05>;
			interrupts = <0x00 0x14 0x04>;
			reg = <0x00 0xff050000 0x00 0x1000>;
			clock-names = "ref_clk", "pclk";
			#address-cells = <0x01>;
			#size-cells = <0x00>;
			power-domains = <0x11 0x24>;
			clocks = <0x04 0x3b 0x04 0x1f>;
			label = "TPM";
			num-cs = <0x01>;
			phandle = <0x68>;

			tpm@0 {
				compatible = "infineon,slb9670", "tcg,tpm_tis-spi";
				reg = <0x00>;
				spi-max-frequency = <0x11a49a0>;
			};
		};

		ttc0: timer@ff110000 {
			compatible = "cdns,ttc";
			status = "okay";
			interrupt-parent = <0x05>;
			interrupts = <0x00 0x24 0x04 0x00 0x25 0x04 0x00 0x26 0x04>;
			reg = <0x00 0xff110000 0x00 0x1000>;
			timer-width = <0x20>;
			power-domains = <0x11 0x18>;
			clocks = <0x04 0x1f>;
			#pwm-cells = <0x03>;
			phandle = <0x20>;
		};

		ttc1: timer@ff120000 {
			compatible = "cdns,ttc";
			status = "disabled";
			interrupt-parent = <0x05>;
			interrupts = <0x00 0x27 0x04 0x00 0x28 0x04 0x00 0x29 0x04>;
			reg = <0x00 0xff120000 0x00 0x1000>;
			timer-width = <0x20>;
			power-domains = <0x11 0x19>;
			clocks = <0x04 0x1f>;
			phandle = <0x69>;
		};

		ttc2: timer@ff130000 {
			compatible = "cdns,ttc";
			status = "disabled";
			interrupt-parent = <0x05>;
			interrupts = <0x00 0x2a 0x04 0x00 0x2b 0x04 0x00 0x2c 0x04>;
			reg = <0x00 0xff130000 0x00 0x1000>;
			timer-width = <0x20>;
			power-domains = <0x11 0x1a>;
			clocks = <0x04 0x1f>;
			phandle = <0x6a>;
		};

		ttc3: timer@ff140000 {
			compatible = "cdns,ttc";
			status = "disabled";
			interrupt-parent = <0x05>;
			interrupts = <0x00 0x2d 0x04 0x00 0x2e 0x04 0x00 0x2f 0x04>;
			reg = <0x00 0xff140000 0x00 0x1000>;
			timer-width = <0x20>;
			power-domains = <0x11 0x1b>;
			clocks = <0x04 0x1f>;
			phandle = <0x6b>;
		};

		uart0: serial@ff000000 {
			u-boot,dm-pre-reloc;
			compatible = "xlnx,zynqmp-uart", "cdns,uart-r1p12";
			status = "okay";
			interrupt-parent = <0x05>;
			interrupts = <0x00 0x15 0x04>;
			reg = <0x00 0xff000000 0x00 0x1000>;
			clock-names = "uart_clk", "pclk";
			power-domains = <0x11 0x21>;
			clocks = <0x04 0x38 0x04 0x1f>;
			phandle = <0x6c>;
		};

		uart1: serial@ff010000 {
			u-boot,dm-pre-reloc;
			compatible = "xlnx,zynqmp-uart", "cdns,uart-r1p12";
			status = "okay";
			interrupt-parent = <0x05>;
			interrupts = <0x00 0x16 0x04>;
			reg = <0x00 0xff010000 0x00 0x1000>;
			clock-names = "uart_clk", "pclk";
			power-domains = <0x11 0x22>;
			clocks = <0x04 0x39 0x04 0x1f>;
			phandle = <0x6d>;
		};

		uart2: serial@ff080000 {
			compatible = "xlnx,zynqmp-uart", "cdns,uart-r1p12";
			status = "okay";
			interrupt-parent = <0x05>;
			interrupts = <0x00 0x30 0x04>;
			reg = <0x00 0xff080000 0x00 0x1000>;
			clock-names = "uart_clk", "pclk";
			power-domains = <0x11 0x21>;
			clocks = <0x04 0x38 0x04 0x1f>;
			phandle = <0xf0>;
		};

		usb0: usb@ff9d0000 {
			#address-cells = <0x02>;
			#size-cells = <0x02>;
			status = "disabled";
			compatible = "xlnx,zynqmp-dwc3";
			reg = <0x00 0xff9d0000 0x00 0x100>;
			clock-names = "bus_clk", "ref_clk";
			power-domains = <0x11 0x16>;
			resets = <0x13 0x3b 0x13 0x3d 0x13 0x3f>;
			reset-names = "usb_crst", "usb_hibrst", "usb_apbrst";
			reset-gpios = <0x18 0x01 0x01>;
			ranges;
			clocks = <0x04 0x20 0x04 0x22>;
			assigned-clocks = <0x04 0x20 0x04 0x22>;
			phandle = <0x6e>;

			dwc3_0: usb@fe200000 {
				compatible = "snps,dwc3";
				status = "disabled";
				reg = <0x00 0xfe200000 0x00 0x40000>;
				interrupt-parent = <0x05>;
				interrupt-names = "dwc_usb3", "otg", "hiber";
				interrupts = <0x00 0x41 0x04 0x00 0x45 0x04 0x00 0x4b 0x04>;
				iommus = <0x12 0x860>;
				snps,quirk-frame-length-adjustment = <0x20>;
				clock-names = "ref";
				snps,enable_guctl1_resume_quirk;
				snps,enable_guctl1_ipd_quirk;
				snps,resume-hs-terminations;
				clocks = <0x04 0x22>;
				phandle = <0x6f>;
			};
		};

		usb1: usb@ff9e0000 {
			#address-cells = <0x02>;
			#size-cells = <0x02>;
			status = "disabled";
			compatible = "xlnx,zynqmp-dwc3";
			reg = <0x00 0xff9e0000 0x00 0x100>;
			clock-names = "bus_clk", "ref_clk";
			power-domains = <0x11 0x17>;
			resets = <0x13 0x3c 0x13 0x3e 0x13 0x40>;
			reset-names = "usb_crst", "usb_hibrst", "usb_apbrst";
			ranges;
			clocks = <0x04 0x21 0x04 0x22>;
			assigned-clocks = <0x04 0x21 0x04 0x22>;
			phandle = <0x70>;

			dwc3_1: usb@fe300000 {
				compatible = "snps,dwc3";
				status = "disabled";
				reg = <0x00 0xfe300000 0x00 0x40000>;
				interrupt-parent = <0x05>;
				interrupt-names = "dwc_usb3", "otg", "hiber";
				interrupts = <0x00 0x46 0x04 0x00 0x4a 0x04 0x00 0x4c 0x04>;
				iommus = <0x12 0x861>;
				snps,quirk-frame-length-adjustment = <0x20>;
				clock-names = "ref";
				snps,enable_guctl1_resume_quirk;
				snps,enable_guctl1_ipd_quirk;
				snps,resume-hs-terminations;
				clocks = <0x04 0x22>;
				phandle = <0x71>;
			};
		};

		watchdog0: watchdog@fd4d0000 {
			compatible = "cdns,wdt-r1p2";
			status = "okay";
			interrupt-parent = <0x05>;
			interrupts = <0x00 0x71 0x01>;
			reg = <0x00 0xfd4d0000 0x00 0x1000>;
			timeout-sec = <0x3c>;
			reset-on-timeout;
			clocks = <0x04 0x4b>;
			phandle = <0x72>;
		};

		lpd_watchdog: watchdog@ff150000 {
			compatible = "cdns,wdt-r1p2";
			status = "okay";
			interrupt-parent = <0x05>;
			interrupts = <0x00 0x34 0x01>;
			reg = <0x00 0xff150000 0x00 0x1000>;
			timeout-sec = <0x0a>;
			clocks = <0x04 0x70>;
			phandle = <0x73>;
		};

		xilinx_ams: ams@ffa50000 {
			compatible = "xlnx,zynqmp-ams";
			status = "okay";
			interrupt-parent = <0x05>;
			interrupts = <0x00 0x38 0x04>;
			interrupt-names = "ams-irq";
			reg = <0x00 0xffa50000 0x00 0x800>;
			reg-names = "ams-base";
			#address-cells = <0x01>;
			#size-cells = <0x01>;
			#io-channel-cells = <0x01>;
			ranges = <0x00 0x00 0xffa50800 0x800>;
			clocks = <0x04 0x46>;
			phandle = <0x1f>;

			ams_ps: ams_ps@0 {
				compatible = "xlnx,zynqmp-ams-ps";
				status = "okay";
				reg = <0x00 0x400>;
				phandle = <0x74>;
			};

			ams_pl: ams_pl@400 {
				compatible = "xlnx,zynqmp-ams-pl";
				status = "okay";
				reg = <0x400 0x400>;
				phandle = <0x75>;
			};
		};

		zynqmp_dpdma: dma-controller@fd4c0000 {
			compatible = "xlnx,zynqmp-dpdma";
			status = "disabled";
			reg = <0x00 0xfd4c0000 0x00 0x1000>;
			interrupts = <0x00 0x7a 0x04>;
			interrupt-parent = <0x05>;
			clock-names = "axi_clk";
			power-domains = <0x11 0x29>;
			dma-channels = <0x06>;
			iommus = <0x12 0xce4>;
			#dma-cells = <0x01>;
			clocks = <0x04 0x14>;
			assigned-clocks = <0x04 0x14>;
			phandle = <0x1a>;
		};

		zynqmp_dpaud_setting: dp_aud@fd4ac000 {
			compatible = "xlnx,zynqmp-dpaud-setting", "syscon";
			reg = <0x00 0xfd4ac000 0x00 0x1000>;
			phandle = <0x19>;
		};

		zynqmp_dpsub: display@fd4a0000 {
			u-boot,dm-pre-reloc;
			compatible = "xlnx,zynqmp-dpsub-1.7";
			status = "okay";
			reg = <0x00 0xfd4a0000 0x00 0x1000 0x00 0xfd4aa000 0x00 0x1000 0x00 0xfd4ab000 0x00 0x1000>;
			reg-names = "dp", "blend", "av_buf";
			xlnx,dpaud-reg = <0x19>;
			interrupts = <0x00 0x77 0x04>;
			interrupt-parent = <0x05>;
			iommus = <0x12 0xce3>;
			clock-names = "dp_apb_clk", "dp_aud_clk", "dp_vtc_pixel_clk_in";
			power-domains = <0x11 0x29>;
			resets = <0x13 0x03>;
			dma-names = "vid0", "vid1", "vid2", "gfx0";
			dmas = <0x1a 0x00 0x1a 0x01 0x1a 0x02 0x1a 0x03>;
			clocks = <0x1b 0x04 0x11 0x04 0x10>;
			assigned-clocks = <0x04 0x12 0x04 0x11 0x04 0x10>;
			phandle = <0x76>;

			i2c-bus {
			};

			zynqmp_dp_snd_codec0: zynqmp_dp_snd_codec0 {
				compatible = "xlnx,dp-snd-codec";
				clock-names = "aud_clk";
				clocks = <0x04 0x11>;
				phandle = <0x1e>;
			};

			zynqmp_dp_snd_pcm0: zynqmp_dp_snd_pcm0 {
				compatible = "xlnx,dp-snd-pcm0";
				dmas = <0x1a 0x04>;
				dma-names = "tx";
				phandle = <0x1c>;
			};

			zynqmp_dp_snd_pcm1: zynqmp_dp_snd_pcm1 {
				compatible = "xlnx,dp-snd-pcm1";
				dmas = <0x1a 0x05>;
				dma-names = "tx";
				phandle = <0x1d>;
			};

			zynqmp_dp_snd_card0: zynqmp_dp_snd_card {
				compatible = "xlnx,dp-snd-card";
				xlnx,dp-snd-pcm = <0x1c 0x1d>;
				xlnx,dp-snd-codec = <0x1e>;
				phandle = <0x77>;
			};
		};

		virtio_matter@fe400200 {
			compatible = "virtio,mmio";
			reg = <0x00 0xfe400200 0x00 0x150>;
			interrupt-parent = <0x05>;
			interrupts = <0x00 0x21 0x04>;
		};
	};

	fclk0: fclk0 {
		status = "okay";
		compatible = "xlnx,fclk";
		clocks = <0x04 0x47>;
		phandle = <0x78>;
	};

	fclk1: fclk1 {
		status = "okay";
		compatible = "xlnx,fclk";
		clocks = <0x04 0x48>;
		phandle = <0x79>;
	};

	fclk2: fclk2 {
		status = "okay";
		compatible = "xlnx,fclk";
		clocks = <0x04 0x49>;
		phandle = <0x7a>;
	};

	fclk3: fclk3 {
		status = "okay";
		compatible = "xlnx,fclk";
		clocks = <0x04 0x4a>;
		phandle = <0x7b>;
	};

	pss_ref_clk: pss_ref_clk {
		u-boot,dm-pre-reloc;
		compatible = "fixed-clock";
		#clock-cells = <0x00>;
		clock-frequency = <0x1fca055>;
		phandle = <0x0b>;
	};

	video_clk: video_clk {
		u-boot,dm-pre-reloc;
		compatible = "fixed-clock";
		#clock-cells = <0x00>;
		clock-frequency = <0x19bfcc0>;
		phandle = <0x0c>;
	};

	pss_alt_ref_clk: pss_alt_ref_clk {
		u-boot,dm-pre-reloc;
		compatible = "fixed-clock";
		#clock-cells = <0x00>;
		clock-frequency = <0x00>;
		phandle = <0x0d>;
	};

	gt_crx_ref_clk: gt_crx_ref_clk {
		u-boot,dm-pre-reloc;
		compatible = "fixed-clock";
		#clock-cells = <0x00>;
		clock-frequency = <0x66ff300>;
		phandle = <0x0f>;
	};

	aux_ref_clk: aux_ref_clk {
		u-boot,dm-pre-reloc;
		compatible = "fixed-clock";
		#clock-cells = <0x00>;
		clock-frequency = <0x19bfcc0>;
		phandle = <0x0e>;
	};

	dp_aclk: dp_aclk {
		compatible = "fixed-clock";
		#clock-cells = <0x00>;
		clock-frequency = <0x5f5e100>;
		clock-accuracy = <0x64>;
		phandle = <0x1b>;
	};

	aliases {
		i2c0 = "/axi/i2c@ff020000";
		i2c1 = "/axi/i2c@ff030000";
		mmc0 = "/axi/mmc@ff160000";
		mmc1 = "/axi/mmc@ff170000";
		nvmem0 = "/axi/i2c@ff030000/eeprom@50";
		nvmem1 = "/axi/i2c@ff030000/eeprom@51";
		rtc0 = "/axi/rtc@ffa60000";
		serial0 = "/axi/serial@ff000000";
		serial1 = "/axi/serial@ff010000";
		serial3 = "/axi/serial@ff080000";
		serial2 = "/dcc";
		spi0 = "/axi/spi@ff0f0000";
		spi1 = "/axi/spi@ff040000";
		spi2 = "/axi/spi@ff050000";
		usb0 = "/axi/usb@ff9d0000";
		usb1 = "/axi/usb@ff9e0000";
	};

	chosen {
		bootargs = "earlycon";
		stdout-path = "serial1:115200n8";
	};

	memory@0 {
		device_type = "memory";
		reg = <0x00 0x00 0x00 0x80000000 0x08 0x00 0x00 0x80000000>;
	};

	gpio-keys {
		compatible = "gpio-keys";
		autorepeat;

		key-fwuen {
			label = "fwuen";
			gpios = <0x14 0x0c 0x01>;
			linux,code = <0x100>;
			wakeup-source;
			autorepeat;
		};
	};

	leds {
		compatible = "gpio-leds";

		ds35-led {
			label = "heartbeat";
			gpios = <0x14 0x07 0x00>;
			linux,default-trigger = "heartbeat";
		};

		ds36-led {
			label = "vbus_det";
			gpios = <0x14 0x08 0x00>;
			default-state = "on";
		};
	};

	ams {
		compatible = "iio-hwmon";
		io-channels = <0x1f 0x00 0x1f 0x01 0x1f 0x02 0x1f 0x03 0x1f 0x04 0x1f 0x05 0x1f 0x06 0x1f 0x07 0x1f 0x08 0x1f 0x09 0x1f 0x0a 0x1f 0x0b 0x1f 0x0c 0x1f 0x0d 0x1f 0x0e 0x1f 0x0f 0x1f 0x10 0x1f 0x11 0x1f 0x12 0x1f 0x13 0x1f 0x14 0x1f 0x15 0x1f 0x16 0x1f 0x17 0x1f 0x18 0x1f 0x19 0x1f 0x1a 0x1f 0x1b 0x1f 0x1c 0x1f 0x1d>;
	};

	pwm-fan {
		compatible = "pwm-fan";
		status = "okay";
		pwms = <0x20 0x02 0x9c40 0x00>;
	};

	__symbols__ {
		cpu0 = "/cpus/cpu@0";
		cpu1 = "/cpus/cpu@1";
		cpu2 = "/cpus/cpu@2";
		cpu3 = "/cpus/cpu@3";
		L2 = "/cpus/l2-cache";
		CPU_SLEEP_0 = "/cpus/idle-states/cpu-sleep-0";
		cpu_opp_table = "/opp-table-cpu";
		zynqmp_ipi = "/zynqmp_ipi";
		ipi_mailbox_pmu1 = "/zynqmp_ipi/mailbox@ff9905c0";
		dcc = "/dcc";
		zynqmp_firmware = "/firmware/zynqmp-firmware";
		zynqmp_power = "/firmware/zynqmp-firmware/zynqmp-power";
		soc_revision = "/firmware/zynqmp-firmware/nvmem_firmware/soc_revision@0";
		efuse_dna = "/firmware/zynqmp-firmware/nvmem_firmware/efuse_dna@c";
		efuse_usr0 = "/firmware/zynqmp-firmware/nvmem_firmware/efuse_usr0@20";
		efuse_usr1 = "/firmware/zynqmp-firmware/nvmem_firmware/efuse_usr1@24";
		efuse_usr2 = "/firmware/zynqmp-firmware/nvmem_firmware/efuse_usr2@28";
		efuse_usr3 = "/firmware/zynqmp-firmware/nvmem_firmware/efuse_usr3@2c";
		efuse_usr4 = "/firmware/zynqmp-firmware/nvmem_firmware/efuse_usr4@30";
		efuse_usr5 = "/firmware/zynqmp-firmware/nvmem_firmware/efuse_usr5@34";
		efuse_usr6 = "/firmware/zynqmp-firmware/nvmem_firmware/efuse_usr6@38";
		efuse_usr7 = "/firmware/zynqmp-firmware/nvmem_firmware/efuse_usr7@3c";
		efuse_miscusr = "/firmware/zynqmp-firmware/nvmem_firmware/efuse_miscusr@40";
		efuse_chash = "/firmware/zynqmp-firmware/nvmem_firmware/efuse_chash@50";
		efuse_pufmisc = "/firmware/zynqmp-firmware/nvmem_firmware/efuse_pufmisc@54";
		efuse_sec = "/firmware/zynqmp-firmware/nvmem_firmware/efuse_sec@58";
		efuse_spkid = "/firmware/zynqmp-firmware/nvmem_firmware/efuse_spkid@5c";
		efuse_ppk0hash = "/firmware/zynqmp-firmware/nvmem_firmware/efuse_ppk0hash@a0";
		efuse_ppk1hash = "/firmware/zynqmp-firmware/nvmem_firmware/efuse_ppk1hash@d0";
		zynqmp_pcap = "/firmware/zynqmp-firmware/pcap";
		zynqmp_reset = "/firmware/zynqmp-firmware/reset-controller";
		pinctrl0 = "/firmware/zynqmp-firmware/pinctrl";
		pinctrl_sdhci0_default = "/firmware/zynqmp-firmware/pinctrl/sdhci0-default";
		modepin_gpio = "/firmware/zynqmp-firmware/gpio";
		zynqmp_clk = "/firmware/zynqmp-firmware/clock-controller";
		fpga_full = "/fpga-full";
		amba = "/axi";
		can0 = "/axi/can@ff060000";
		can1 = "/axi/can@ff070000";
		cci = "/axi/cci@fd6e0000";
		fpd_dma_chan1 = "/axi/dma-controller@fd500000";
		fpd_dma_chan2 = "/axi/dma-controller@fd510000";
		fpd_dma_chan3 = "/axi/dma-controller@fd520000";
		fpd_dma_chan4 = "/axi/dma-controller@fd530000";
		fpd_dma_chan5 = "/axi/dma-controller@fd540000";
		fpd_dma_chan6 = "/axi/dma-controller@fd550000";
		fpd_dma_chan7 = "/axi/dma-controller@fd560000";
		fpd_dma_chan8 = "/axi/dma-controller@fd570000";
		gic = "/axi/interrupt-controller@f9010000";
		gpu = "/axi/gpu@fd4b0000";
		lpd_dma_chan1 = "/axi/dma-controller@ffa80000";
		lpd_dma_chan2 = "/axi/dma-controller@ffa90000";
		lpd_dma_chan3 = "/axi/dma-controller@ffaa0000";
		lpd_dma_chan4 = "/axi/dma-controller@ffab0000";
		lpd_dma_chan5 = "/axi/dma-controller@ffac0000";
		lpd_dma_chan6 = "/axi/dma-controller@ffad0000";
		lpd_dma_chan7 = "/axi/dma-controller@ffae0000";
		lpd_dma_chan8 = "/axi/dma-controller@ffaf0000";
		mc = "/axi/memory-controller@fd070000";
		nand0 = "/axi/nand-controller@ff100000";
		gem0 = "/axi/ethernet@ff0b0000";
		gem1 = "/axi/ethernet@ff0c0000";
		gem2 = "/axi/ethernet@ff0d0000";
		gem3 = "/axi/ethernet@ff0e0000";
		gpio = "/axi/gpio@ff0a0000";
		i2c0 = "/axi/i2c@ff020000";
		i2c1 = "/axi/i2c@ff030000";
		eeprom = "/axi/i2c@ff030000/eeprom@50";
		eeprom_cc = "/axi/i2c@ff030000/eeprom@51";
		da9131 = "/axi/i2c@ff030000/pmic@33";
		da9131_buck1 = "/axi/i2c@ff030000/pmic@33/regulators/buck1";
		da9131_buck2 = "/axi/i2c@ff030000/pmic@33/regulators/buck2";
		da9130 = "/axi/i2c@ff030000/pmic@32";
		da9130_buck1 = "/axi/i2c@ff030000/pmic@32/regulators/buck1";
		ocm = "/axi/memory-controller@ff960000";
		perf_monitor_ocm = "/axi/perf-monitor@ffa00000";
		perf_monitor_ddr = "/axi/perf-monitor@fd0b0000";
		perf_monitor_cci = "/axi/perf-monitor@fd490000";
		perf_monitor_lpd = "/axi/perf-monitor@ffa10000";
		pcie = "/axi/pcie@fd0e0000";
		pcie_intc = "/axi/pcie@fd0e0000/legacy-interrupt-controller";
		qspi = "/axi/spi@ff0f0000";
		spi_flash = "/axi/spi@ff0f0000/flash@0";
		psgtr = "/axi/phy@fd400000";
		rtc = "/axi/rtc@ffa60000";
		sata = "/axi/ahci@fd0c0000";
		sdhci0 = "/axi/mmc@ff160000";
		sdhci1 = "/axi/mmc@ff170000";
		smmu = "/axi/iommu@fd800000";
		spi0 = "/axi/spi@ff040000";
		spi1 = "/axi/spi@ff050000";
		ttc0 = "/axi/timer@ff110000";
		ttc1 = "/axi/timer@ff120000";
		ttc2 = "/axi/timer@ff130000";
		ttc3 = "/axi/timer@ff140000";
		uart0 = "/axi/serial@ff000000";
		uart1 = "/axi/serial@ff010000";
		uart2 = "/axi/serial@ff080000";
		usb0 = "/axi/usb@ff9d0000";
		dwc3_0 = "/axi/usb@ff9d0000/usb@fe200000";
		usb1 = "/axi/usb@ff9e0000";
		dwc3_1 = "/axi/usb@ff9e0000/usb@fe300000";
		watchdog0 = "/axi/watchdog@fd4d0000";
		lpd_watchdog = "/axi/watchdog@ff150000";
		xilinx_ams = "/axi/ams@ffa50000";
		ams_ps = "/axi/ams@ffa50000/ams_ps@0";
		ams_pl = "/axi/ams@ffa50000/ams_pl@400";
		zynqmp_dpdma = "/axi/dma-controller@fd4c0000";
		zynqmp_dpaud_setting = "/axi/dp_aud@fd4ac000";
		zynqmp_dpsub = "/axi/display@fd4a0000";
		zynqmp_dp_snd_codec0 = "/axi/display@fd4a0000/zynqmp_dp_snd_codec0";
		zynqmp_dp_snd_pcm0 = "/axi/display@fd4a0000/zynqmp_dp_snd_pcm0";
		zynqmp_dp_snd_pcm1 = "/axi/display@fd4a0000/zynqmp_dp_snd_pcm1";
		zynqmp_dp_snd_card0 = "/axi/display@fd4a0000/zynqmp_dp_snd_card";
		fclk0 = "/fclk0";
		fclk1 = "/fclk1";
		fclk2 = "/fclk2";
		fclk3 = "/fclk3";
		pss_ref_clk = "/pss_ref_clk";
		video_clk = "/video_clk";
		pss_alt_ref_clk = "/pss_alt_ref_clk";
		gt_crx_ref_clk = "/gt_crx_ref_clk";
		aux_ref_clk = "/aux_ref_clk";
		dp_aclk = "/dp_aclk";
	};
};
